VERSION ""

NS_ :

BS_:

BU_:

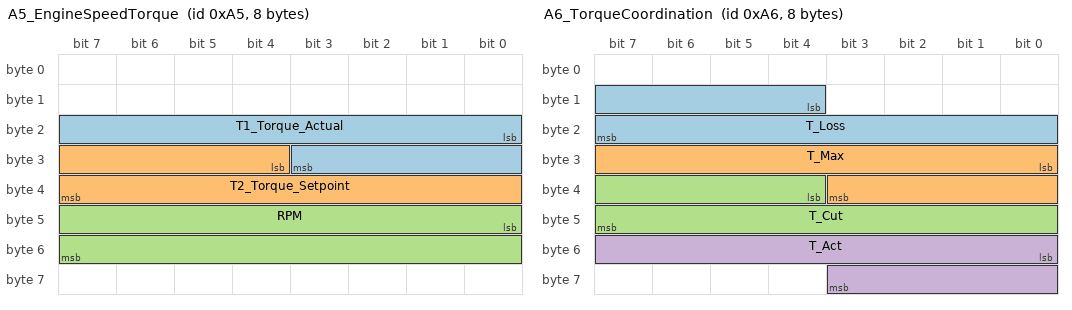
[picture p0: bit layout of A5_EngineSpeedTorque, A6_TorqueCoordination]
BO_ 165 A5_EngineSpeedTorque: 8 Vector__XXX
 SG_ T1_Torque_Actual   : 16|12@1+ (0.5,-999.5) [-999.5|1048.0] "Nm" Vector__XXX
 SG_ T2_Torque_Setpoint : 28|12@1+ (0.5,-999.5) [-999.5|1048.0] "Nm" Vector__XXX
 SG_ RPM                : 40|16@1+ (0.25,0)     [0|16383.75]    "rpm" Vector__XXX

BO_ 166 A6_TorqueCoordination: 8 Vector__XXX
 SG_ T_Loss : 12|12@1+ (0.5,-999.5) [-999.5|1048.0] "Nm" Vector__XXX
 SG_ T_Max  : 24|12@1+ (0.5,-999.5) [-999.5|1048.0] "Nm" Vector__XXX
 SG_ T_Cut  : 36|12@1+ (0.5,-999.5) [-999.5|1048.0] "Nm" Vector__XXX
 SG_ T_Act  : 48|12@1+ (0.5,-999.5) [-999.5|1048.0] "Nm" Vector__XXX

BO_ 167 A7_AirFuelManagement: 7 Vector__XXX
 SG_ T_Demand   : 12|12@1+ (0.5,-999.5)        [-999.5|1048.0] "Nm" Vector__XXX
 SG_ Phi_Demand : 32|16@1+ (3.0518e-5,0)        [0|1.5]         ""  Vector__XXX

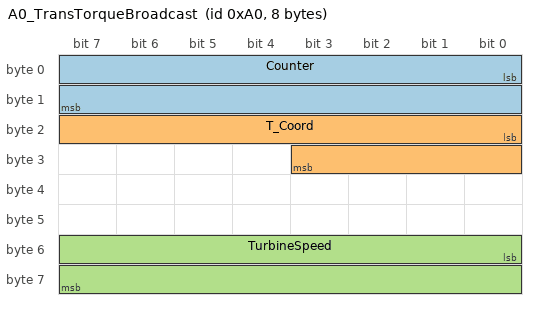
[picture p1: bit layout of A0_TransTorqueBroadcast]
BO_ 160 A0_TransTorqueBroadcast: 8 Vector__XXX
 SG_ Counter      :  0|16@1+ (1,0)        [0|65535]       ""    Vector__XXX
 SG_ T_Coord      : 16|12@1+ (0.5,-999.5) [-999.5|1048.0] "Nm"  Vector__XXX
 SG_ TurbineSpeed : 48|16@1+ (1,-2000)    [0|14000]        "rpm" Vector__XXX

BO_ 176 B0_TransTorqueMgmt: 8 Vector__XXX
 SG_ AliveCounter  :  0|16@1+ (1,0)        [0|65535]       ""   Vector__XXX
 SG_ B0_T1         : 12|12@1+ (0.5,-999.5) [-999.5|1048.0] "Nm" Vector__XXX
 SG_ B0_ShiftCeil  : 24|12@1+ (0.5,-999.5) [-999.5|1048.0] "Nm" Vector__XXX
 SG_ B0_T3         : 36|12@1+ (0.5,-999.5) [-999.5|1048.0] "Nm" Vector__XXX

BO_ 143 X8F_PhiSetpoint: 8 Vector__XXX
 SG_ Phi_Soll : 16|16@1+ (3.0518e-5,0) [0|1.5] "" Vector__XXX

BO_ 217 D9_PedalPosition: 8 Vector__XXX
 SG_ Pedal_Raw : 16|12@1+ (1,0) [0|4095] "" Vector__XXX
